# WS53 register map
File version: 0.1.0-experimental
Registers are 32-bit, read-write, no defined reset value unless marked. A register's access mark holds for its fields unless they carry their own. Offsets are from the block's base; [hi:lo] are bit positions; lines under a group give offsets from that group; {n}, {i} and the like mark numbered series; 'fields as' and 'values as' point back to an identical list.

## PINMUX_MCU
Base 0x52008000
0x00 MGPIO0_SEL
  [2:0] MODE — Pin-specific mux selection; legal functions depend on the pad
{0x0+4i} MGPIO{i}_SEL (i=2..5)
  fields as MGPIO0_SEL
{0x0+4i} MGPIO{i}_SEL (i=8..10)
  fields as MGPIO0_SEL
{0x0+4i} MGPIO{i}_SEL (i=12..15)
  fields as MGPIO0_SEL
{0x0+4i} MGPIO{i}_SEL (i=17..22)
  fields as MGPIO0_SEL

## TRNG
Base 0x52024000
0x100 FIFO_DATA ro read-has-side-effects — Consume one FIFO word; SDK reads twice per candidate and discards the comparison word
  [31:0] VALUE read-has-side-effects
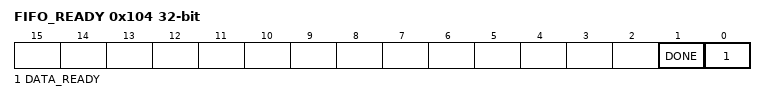
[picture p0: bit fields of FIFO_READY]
0x104 FIFO_READY ro — Both data_ready and done must be set before the SDK consumes a candidate
  [1] DONE, [0] DATA_READY
0x174 FRO_SAMPLE_CLK_SEL — Optional FRO entropy-source clock selector; SDK writes 1 for internal FRO
  [0] INTERNAL_FRO
0x178 FRO_DIV_CNT — Optional FRO divider encoding; SDK uses 0x1b for its divide-by-54 setup
  [7:0] VALUE

## I2S
Base 0x52030000
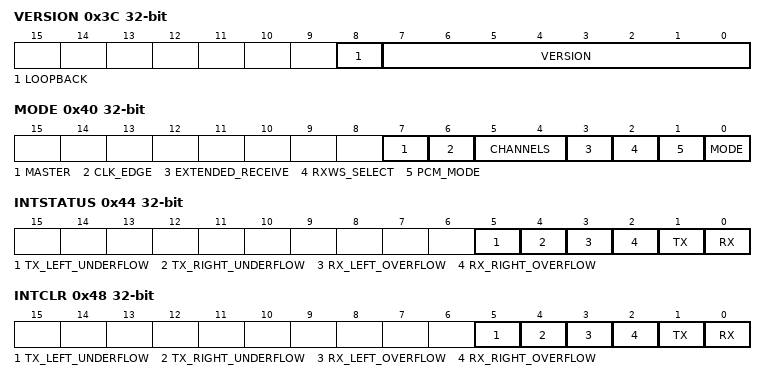
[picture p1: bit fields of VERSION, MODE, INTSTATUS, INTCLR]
0x3C VERSION access per field
  [8] LOOPBACK rw, [7:0] VERSION ro
0x40 MODE
  [7] MASTER — 0 slave, 1 master
  [6] CLK_EDGE — 0 falling, 1 rising; SDK configure selects rising
  [5:4] CHANNELS — 0/1/2/3 encode 2/4/8/16 channels
  [3] EXTENDED_RECEIVE
  [2] RXWS_SELECT
  [1] PCM_MODE — PCM self-defined timing selection
  [0] MODE — 0 I2S, 1 PCM
0x44 INTSTATUS ro
  [5] TX_LEFT_UNDERFLOW, [4] TX_RIGHT_UNDERFLOW, [3] RX_LEFT_OVERFLOW, [2] RX_RIGHT_OVERFLOW, [1] TX, [0] RX
0x48 INTCLR wo — Acknowledge interrupt sources by writing their bits; no readback contract
  [5] TX_LEFT_UNDERFLOW write-1-clears, [4] TX_RIGHT_UNDERFLOW write-1-clears, [3] RX_LEFT_OVERFLOW write-1-clears, [2] RX_RIGHT_OVERFLOW write-1-clears, [1] TX write-1-clears, [0] RX write-1-clears
0x4C LEFT_TX wo
  [31:0] DATA
0x50 RIGHT_TX wo
  [31:0] DATA
0x54 LEFT_RX ro read-has-side-effects
  [31:0] DATA read-has-side-effects
0x58 RIGHT_RX ro read-has-side-effects
  [31:0] DATA read-has-side-effects
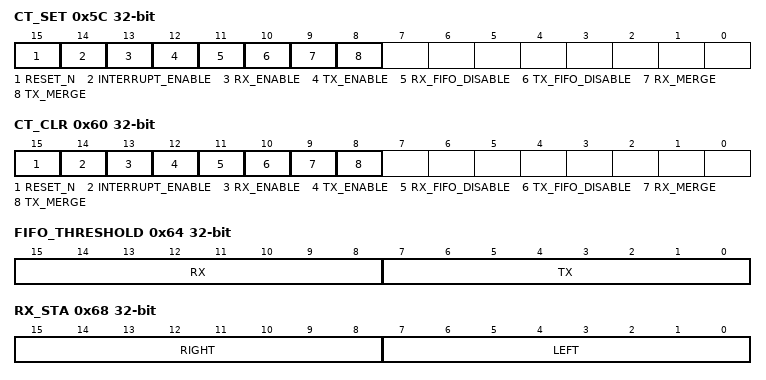
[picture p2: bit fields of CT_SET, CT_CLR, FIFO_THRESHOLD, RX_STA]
0x5C CT_SET wo — Set control command view; SDK writes one to enable/release reset; readback and zero-write effects unverified
  [15] RESET_N, [14] INTERRUPT_ENABLE, [13] RX_ENABLE, [12] TX_ENABLE, [11] RX_FIFO_DISABLE, [10] TX_FIFO_DISABLE, [9] RX_MERGE, [8] TX_MERGE
0x60 CT_CLR wo — Clear control command view; SDK writes one to disable/assert reset; readback and zero-write effects unverified
  fields as CT_SET
0x64 FIFO_THRESHOLD
  [15:8] RX, [7:0] TX
0x68 RX_STA ro
  [15:8] RIGHT, [7:0] LEFT
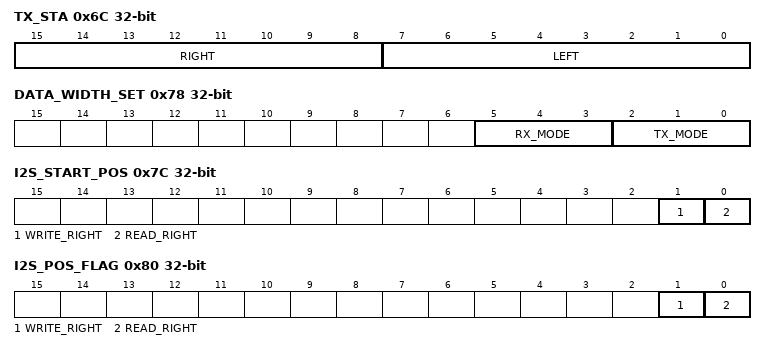
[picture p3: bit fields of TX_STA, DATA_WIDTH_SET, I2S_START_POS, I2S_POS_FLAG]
0x6C TX_STA ro
  [15:8] RIGHT, [7:0] LEFT
0x78 DATA_WIDTH_SET
  [5:3] RX_MODE range 1..5 — 1/2/3/4/5 encode 16/18/20/24/32 bits; zero reserved
    1=Bits16 (16-bit samples); 2=Bits18 (18-bit samples); 3=Bits20 (20-bit samples); 4=Bits24 (24-bit samples); 5=Bits32 (32-bit samples)
  [2:0] TX_MODE range 1..5 — 1/2/3/4/5 encode 16/18/20/24/32 bits; zero reserved
    values as RX_MODE
0x7C I2S_START_POS
  [1] WRITE_RIGHT — 0 left, 1 right
  [0] READ_RIGHT — 0 left, 1 right
0x80 I2S_POS_FLAG — Position flags: SDK writes zero during configure; autonomous behavior unverified
  [1] WRITE_RIGHT, [0] READ_RIGHT
0x84 SIGNED_EXT
  [0] ENABLE
0x88 I2S_POS_MERGE_EN
  [0] ENABLE
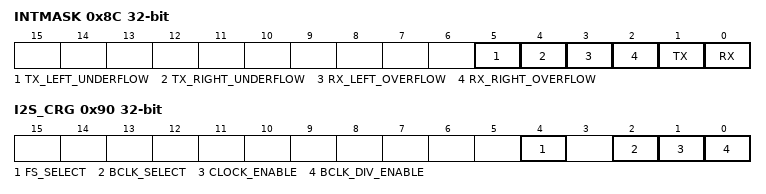
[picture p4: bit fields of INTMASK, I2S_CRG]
0x8C INTMASK — Interrupt mask: one masks, zero enables; SDK write mask 0x3d and read mask 0x3e
  fields as INTSTATUS
0x90 I2S_CRG
  [4] FS_SELECT, [2] BCLK_SELECT, [1] CLOCK_ENABLE, [0] BCLK_DIV_ENABLE
0x94 I2S_BCLK_DIV_NUM
  [6:0] DIVIDER
0x98 I2S_FS_DIV_NUM
  [9:0] DIVIDER
0x9C I2S_FS_DIV_RATIO_NUM
  [10:0] RATIO
0xA0 I2S_DUAL_RX_CHN ro read-has-side-effects
  [31:0] DATA read-has-side-effects
0xC0 I2S_DUAL_TX_CHN wo
  [31:0] DATA

## MDMA
Base 0x52070000
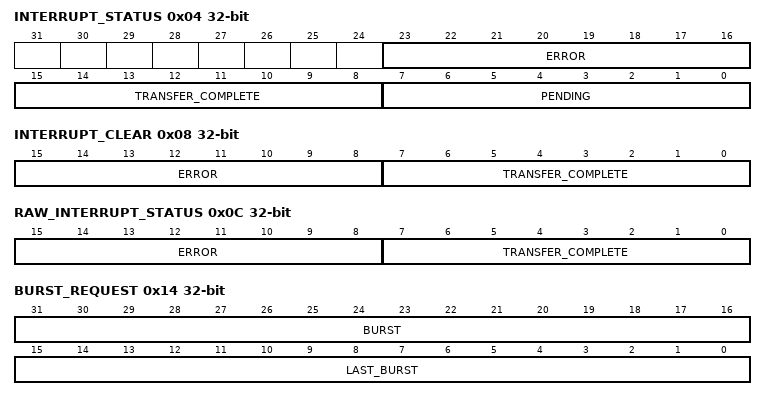
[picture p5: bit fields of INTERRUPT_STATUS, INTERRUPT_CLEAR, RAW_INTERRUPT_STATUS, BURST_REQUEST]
0x04 INTERRUPT_STATUS ro
  [23:16] ERROR, [15:8] TRANSFER_COMPLETE, [7:0] PENDING
0x08 INTERRUPT_CLEAR wo — Command view: write one to acknowledge selected channels. ROM uses RMW, but readback is not specified; deliberately no read/modify API.
  [15:8] ERROR write-1-clears, [7:0] TRANSFER_COMPLETE write-1-clears
0x0C RAW_INTERRUPT_STATUS ro
  [15:8] ERROR, [7:0] TRANSFER_COMPLETE
0x10 ENABLED_CHANNELS ro
  [7:0] CHANNELS
0x14 BURST_REQUEST
  [31:16] BURST, [15:0] LAST_BURST
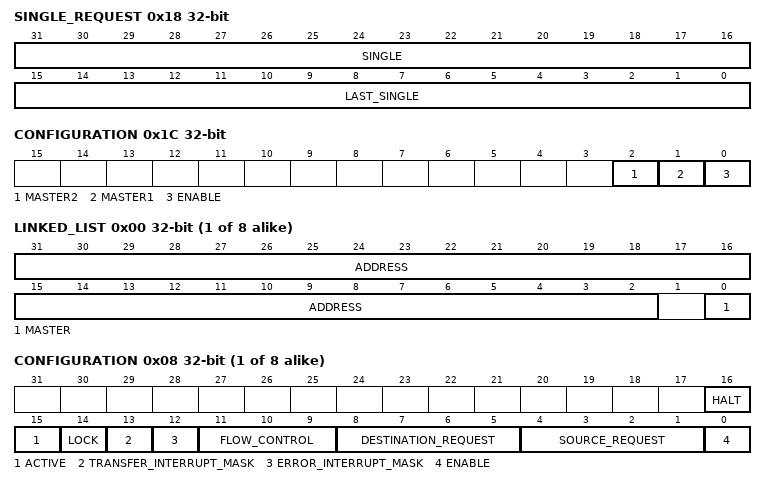
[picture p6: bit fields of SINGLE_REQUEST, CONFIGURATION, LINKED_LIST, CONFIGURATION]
0x18 SINGLE_REQUEST
  [31:16] SINGLE, [15:0] LAST_SINGLE
0x1C CONFIGURATION
  [2] MASTER2, [1] MASTER1, [0] ENABLE
0x20 SYNC
  [15:0] REQUESTS
{0x100+0x20*i} CHANNEL[{i}] (i=0..7) group
  0x00 LINKED_LIST
    [31:2] ADDRESS, [0] MASTER
  0x04 DESTINATION
    [31:0] ADDRESS — Program destination address. Initial A-board memory-copy HIL reads the last transferred element after completion, not one-past; peripheral/partial progress remains unqualified.
  0x08 CONFIGURATION access per field
    [16] HALT rw
    [15] ACTIVE ro — Status-only view of SDK active bit; writable behavior and quiescence timing are not established
    [14] LOCK rw
    [13] TRANSFER_INTERRUPT_MASK rw
    [12] ERROR_INTERRUPT_MASK rw
    [11:9] FLOW_CONTROL rw
    [8:5] DESTINATION_REQUEST rw
      0=I2C0_TX; 1=I2C0_RX; 2=I2C1_TX; 3=I2C1_RX; 4=QSPI1_TX; 5=QSPI1_RX; 6=SPI0_TX; 7=SPI0_RX; 8=UART1_TX; 9=UART1_RX; 10=UART0_TX; 11=UART0_RX; 12=I2S_TX; 13=I2S_RX; 14=PWM; 15=SPWM
    [4:1] SOURCE_REQUEST rw
      values as DESTINATION_REQUEST
    [0] ENABLE rw
  0x10 SOURCE
    [31:0] ADDRESS — Program source address. Initial A-board memory-copy HIL reads the last transferred element after completion, not one-past; peripheral/partial progress remains unqualified.
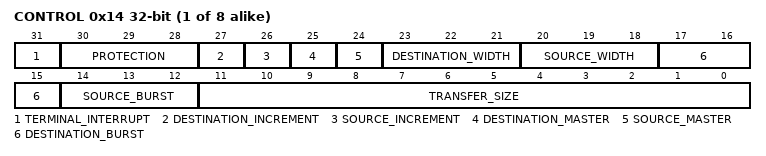
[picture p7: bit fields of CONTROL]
  0x14 CONTROL
    [31] TERMINAL_INTERRUPT
    [30:28] PROTECTION
    [27] DESTINATION_INCREMENT
    [26] SOURCE_INCREMENT
    [25] DESTINATION_MASTER
    [24] SOURCE_MASTER
    [23:21] DESTINATION_WIDTH
    [20:18] SOURCE_WIDTH
    [17:15] DESTINATION_BURST
    [14:12] SOURCE_BURST
    [11:0] TRANSFER_SIZE — Write element count. Readback is status, not a programming echo: initial A-board HIL reads zero before enabling and after completion despite a successful17-element transfer. Active/partial readback semantics remain unqualified.
